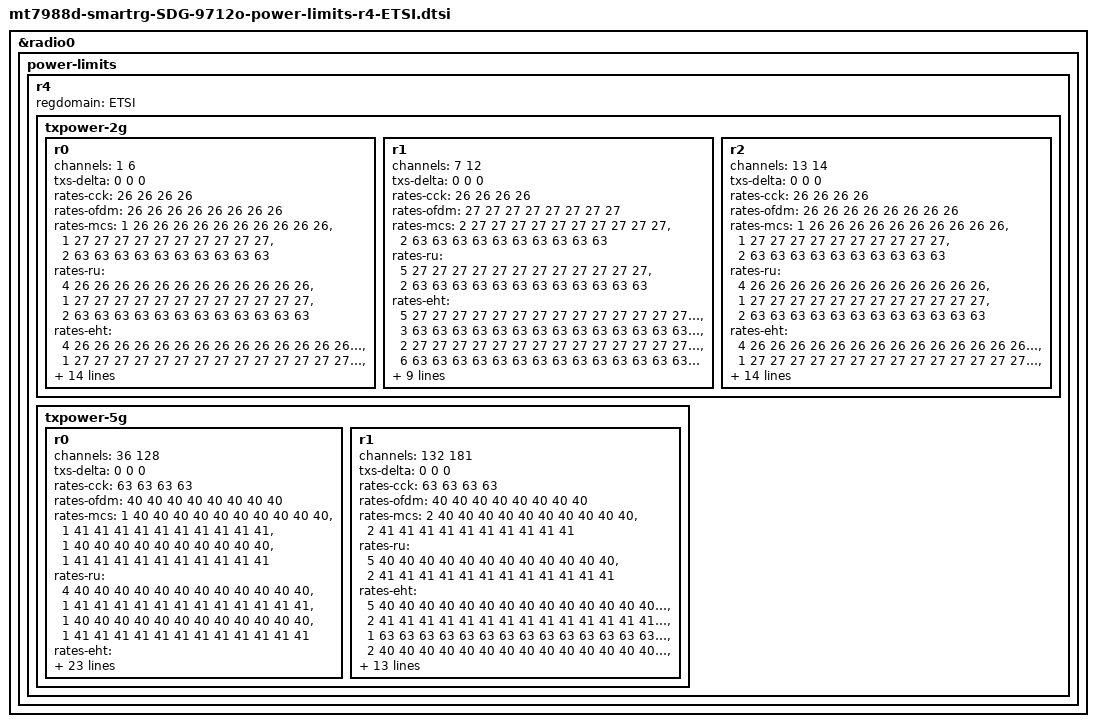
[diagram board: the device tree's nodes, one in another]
// SPDX-License-Identifier: (GPL-2.0 OR MIT)
/*
 * Copyright (C) 2024 SmartRG Inc.
 * Author: Chad Monroe <chad.monroe@smartrg.com>
 */

&radio0 {
	power-limits {
		r4 {
			regdomain = "ETSI";

			txpower-2g {
				r0 {
					channels = <1 6>;
					txs-delta = <0 0 0>;
					rates-cck = /bits/ 8 <26 26 26 26>;
					rates-ofdm = /bits/ 8 <26 26 26 26 26 26 26 26>;
					rates-mcs =
					/bits/ 8 <1 26 26 26 26 26 26 26 26 26 26>,
					/bits/ 8 <1 27 27 27 27 27 27 27 27 27 27>,
					/bits/ 8 <2 63 63 63 63 63 63 63 63 63 63>;
					rates-ru =
					/bits/ 8 <4 26 26 26 26 26 26 26 26 26 26 26 26>,
					/bits/ 8 <1 27 27 27 27 27 27 27 27 27 27 27 27>,
					/bits/ 8 <2 63 63 63 63 63 63 63 63 63 63 63 63>;
					rates-eht =
					/bits/ 8 <4 26 26 26 26 26 26 26 26 26 26 26 26 26 26 26 26>,
					/bits/ 8 <1 27 27 27 27 27 27 27 27 27 27 27 27 27 27 27 27>,
					/bits/ 8 <3 63 63 63 63 63 63 63 63 63 63 63 63 63 63 63 63>,
					/bits/ 8 <2 26 26 26 26 26 26 26 26 26 26 26 26 26 26 26 26>,
					/bits/ 8 <6 63 63 63 63 63 63 63 63 63 63 63 63 63 63 63 63>;
					paths-cck = /bits/ 8 <26 20 16 14 12>;
					paths-ofdm = /bits/ 8 <26 20 16 14 12>;
					paths-ofdm-bf = /bits/ 8 <14 7 2 0>;
					paths-ru =
					/bits/ 8 <6 26 20 16 14 12 20 16 14 12 16 14 12 14 12 12>,
					/bits/ 8 <1 27 21 17 15 13 21 17 15 13 17 15 13 15 13 13>,
					/bits/ 8 <9 63 63 63 63 63 63 63 63 63 63 63 63 63 63 63>;
					paths-ru-bf =
					/bits/ 8 <6 26 14 7 2 0 20 13 8 4 16 11 8 14 10 12>,
					/bits/ 8 <1 27 15 8 3 0 21 14 9 5 17 12 9 15 11 13>,
					/bits/ 8 <9 63 63 63 63 63 63 63 63 63 63 63 63 63 63 63>;
				};
				r1 {
					channels = <7 12>;
					txs-delta = <0 0 0>;
					rates-cck = /bits/ 8 <26 26 26 26>;
					rates-ofdm = /bits/ 8 <27 27 27 27 27 27 27 27>;
					rates-mcs =
					/bits/ 8 <2 27 27 27 27 27 27 27 27 27 27>,
					/bits/ 8 <2 63 63 63 63 63 63 63 63 63 63>;
					rates-ru =
					/bits/ 8 <5 27 27 27 27 27 27 27 27 27 27 27 27>,
					/bits/ 8 <2 63 63 63 63 63 63 63 63 63 63 63 63>;
					rates-eht =
					/bits/ 8 <5 27 27 27 27 27 27 27 27 27 27 27 27 27 27 27 27>,
					/bits/ 8 <3 63 63 63 63 63 63 63 63 63 63 63 63 63 63 63 63>,
					/bits/ 8 <2 27 27 27 27 27 27 27 27 27 27 27 27 27 27 27 27>,
					/bits/ 8 <6 63 63 63 63 63 63 63 63 63 63 63 63 63 63 63 63>;
					paths-cck = /bits/ 8 <26 20 16 14 12>;
					paths-ofdm = /bits/ 8 <27 21 17 15 13>;
					paths-ofdm-bf = /bits/ 8 <15 8 3 0>;
					paths-ru =
					/bits/ 8 <7 27 21 17 15 13 21 17 15 13 17 15 13 15 13 13>,
					/bits/ 8 <9 63 63 63 63 63 63 63 63 63 63 63 63 63 63 63>;
					paths-ru-bf =
					/bits/ 8 <7 27 15 8 3 0 21 14 9 5 17 12 9 15 11 13>,
					/bits/ 8 <9 63 63 63 63 63 63 63 63 63 63 63 63 63 63 63>;
				};
				r2 {
					channels = <13 14>;
					txs-delta = <0 0 0>;
					rates-cck = /bits/ 8 <26 26 26 26>;
					rates-ofdm = /bits/ 8 <26 26 26 26 26 26 26 26>;
					rates-mcs =
					/bits/ 8 <1 26 26 26 26 26 26 26 26 26 26>,
					/bits/ 8 <1 27 27 27 27 27 27 27 27 27 27>,
					/bits/ 8 <2 63 63 63 63 63 63 63 63 63 63>;
					rates-ru =
					/bits/ 8 <4 26 26 26 26 26 26 26 26 26 26 26 26>,
					/bits/ 8 <1 27 27 27 27 27 27 27 27 27 27 27 27>,
					/bits/ 8 <2 63 63 63 63 63 63 63 63 63 63 63 63>;
					rates-eht =
					/bits/ 8 <4 26 26 26 26 26 26 26 26 26 26 26 26 26 26 26 26>,
					/bits/ 8 <1 27 27 27 27 27 27 27 27 27 27 27 27 27 27 27 27>,
					/bits/ 8 <3 63 63 63 63 63 63 63 63 63 63 63 63 63 63 63 63>,
					/bits/ 8 <2 26 26 26 26 26 26 26 26 26 26 26 26 26 26 26 26>,
					/bits/ 8 <6 63 63 63 63 63 63 63 63 63 63 63 63 63 63 63 63>;
					paths-cck = /bits/ 8 <26 20 16 14 12>;
					paths-ofdm = /bits/ 8 <26 20 16 14 12>;
					paths-ofdm-bf = /bits/ 8 <14 7 2 0>;
					paths-ru =
					/bits/ 8 <6 26 20 16 14 12 20 16 14 12 16 14 12 14 12 12>,
					/bits/ 8 <1 27 21 17 15 13 21 17 15 13 17 15 13 15 13 13>,
					/bits/ 8 <9 63 63 63 63 63 63 63 63 63 63 63 63 63 63 63>;
					paths-ru-bf =
					/bits/ 8 <6 26 14 7 2 0 20 13 8 4 16 11 8 14 10 12>,
					/bits/ 8 <1 27 15 8 3 0 21 14 9 5 17 12 9 15 11 13>,
					/bits/ 8 <9 63 63 63 63 63 63 63 63 63 63 63 63 63 63 63>;
				};
			};
			txpower-5g {
				r0 {
					channels = <36 128>;
					txs-delta = <0 0 0>;
					rates-cck = /bits/ 8 <63 63 63 63>;
					rates-ofdm = /bits/ 8 <40 40 40 40 40 40 40 40>;
					rates-mcs =
					/bits/ 8 <1 40 40 40 40 40 40 40 40 40 40>,
					/bits/ 8 <1 41 41 41 41 41 41 41 41 41 41>,
					/bits/ 8 <1 40 40 40 40 40 40 40 40 40 40>,
					/bits/ 8 <1 41 41 41 41 41 41 41 41 41 41>;
					rates-ru =
					/bits/ 8 <4 40 40 40 40 40 40 40 40 40 40 40 40>,
					/bits/ 8 <1 41 41 41 41 41 41 41 41 41 41 41 41>,
					/bits/ 8 <1 40 40 40 40 40 40 40 40 40 40 40 40>,
					/bits/ 8 <1 41 41 41 41 41 41 41 41 41 41 41 41>;
					rates-eht =
					/bits/ 8 <4 40 40 40 40 40 40 40 40 40 40 40 40 40 40 40 40>,
					/bits/ 8 <1 41 41 41 41 41 41 41 41 41 41 41 41 41 41 41 41>,
					/bits/ 8 <1 40 40 40 40 40 40 40 40 40 40 40 40 40 40 40 40>,
					/bits/ 8 <1 41 41 41 41 41 41 41 41 41 41 41 41 41 41 41 41>,
					/bits/ 8 <1 63 63 63 63 63 63 63 63 63 63 63 63 63 63 63 63>,
					/bits/ 8 <3 40 40 40 40 40 40 40 40 40 40 40 40 40 40 40 40>,
					/bits/ 8 <2 41 41 41 41 41 41 41 41 41 41 41 41 41 41 41 41>,
					/bits/ 8 <3 63 63 63 63 63 63 63 63 63 63 63 63 63 63 63 63>;
					paths-cck = /bits/ 8 <63 63 63 63 63>;
					paths-ofdm = /bits/ 8 <40 34 30 28 26>;
					paths-ofdm-bf = /bits/ 8 <28 21 16 12>;
					paths-ru =
					/bits/ 8 <6 40 34 30 28 26 34 30 28 26 30 28 26 28 26 26>,
					/bits/ 8 <1 41 35 31 29 27 35 31 29 27 31 29 27 29 27 27>,
					/bits/ 8 <2 40 34 30 28 26 34 30 28 26 30 28 26 28 26 26>,
					/bits/ 8 <3 41 35 31 29 27 35 31 29 27 31 29 27 29 27 27>,
					/bits/ 8 <4 63 63 63 63 63 63 63 63 63 63 63 63 63 63 63>;
					paths-ru-bf =
					/bits/ 8 <6 40 28 21 16 12 34 27 22 18 30 25 22 28 24 26>,
					/bits/ 8 <1 41 29 22 17 13 35 28 23 19 31 26 23 29 25 27>,
					/bits/ 8 <2 40 28 21 16 12 34 27 22 18 30 25 22 28 24 26>,
					/bits/ 8 <3 41 29 22 17 13 35 28 23 19 31 26 23 29 25 27>,
					/bits/ 8 <4 63 63 63 63 63 63 63 63 63 63 63 63 63 63 63>;
				};
				r1 {
					channels = <132 181>;
					txs-delta = <0 0 0>;
					rates-cck = /bits/ 8 <63 63 63 63>;
					rates-ofdm = /bits/ 8 <40 40 40 40 40 40 40 40>;
					rates-mcs =
					/bits/ 8 <2 40 40 40 40 40 40 40 40 40 40>,
					/bits/ 8 <2 41 41 41 41 41 41 41 41 41 41>;
					rates-ru =
					/bits/ 8 <5 40 40 40 40 40 40 40 40 40 40 40 40>,
					/bits/ 8 <2 41 41 41 41 41 41 41 41 41 41 41 41>;
					rates-eht =
					/bits/ 8 <5 40 40 40 40 40 40 40 40 40 40 40 40 40 40 40 40>,
					/bits/ 8 <2 41 41 41 41 41 41 41 41 41 41 41 41 41 41 41 41>,
					/bits/ 8 <1 63 63 63 63 63 63 63 63 63 63 63 63 63 63 63 63>,
					/bits/ 8 <2 40 40 40 40 40 40 40 40 40 40 40 40 40 40 40 40>,
					/bits/ 8 <3 41 41 41 41 41 41 41 41 41 41 41 41 41 41 41 41>,
					/bits/ 8 <3 63 63 63 63 63 63 63 63 63 63 63 63 63 63 63 63>;
					paths-cck = /bits/ 8 <63 63 63 63 63>;
					paths-ofdm = /bits/ 8 <40 34 30 28 26>;
					paths-ofdm-bf = /bits/ 8 <28 21 16 12>;
					paths-ru =
					/bits/ 8 <7 40 34 30 28 26 34 30 28 26 30 28 26 28 26 26>,
					/bits/ 8 <5 41 35 31 29 27 35 31 29 27 31 29 27 29 27 27>,
					/bits/ 8 <4 63 63 63 63 63 63 63 63 63 63 63 63 63 63 63>;
					paths-ru-bf =
					/bits/ 8 <7 40 28 21 16 12 34 27 22 18 30 25 22 28 24 26>,
					/bits/ 8 <5 41 29 22 17 13 35 28 23 19 31 26 23 29 25 27>,
					/bits/ 8 <4 63 63 63 63 63 63 63 63 63 63 63 63 63 63 63>;
				};
			};
		};
	};
};
